# NUC400_v1 register map
File version: 1.0
NUC400_v1 SVD file
Registers are 32-bit, read-write, reset 0x0 unless marked. A register's access mark holds for its fields unless they carry their own. Offsets are from the block's base; lines under a group give offsets from that group; [hi:lo] are bit positions; {n}, {i} and the like mark numbered series; 'fields as' and 'values as' point back to an identical list; <NAME> marks a mode.

## Memory map
0x40000000 SYS blocks up to offset 0x104 — SYS Register Map
0x40000200 CLK blocks up to offset 0x74 — CLK Register Map
0x40000300 NMI size 0x8 — NMI Register Map
0x40004000 GPIO blocks up to offset 0xA40 — GPIO Register Map
0x40008000 PDMA blocks up to offset 0x490 — PDMA Register Map
0x40009000 USBH blocks up to offset 0x208 — USBH Register Map
0x4000B000 EMAC blocks up to offset 0x130 — EMAC Register Map
0x4000C000 FMC blocks up to offset 0xC8 — FMC Register Map
0x4000D000 SDH blocks up to offset 0x840 — SDH Register Map
0x40010000 EBI size 0x24 — EBI Register Map
0x40019000 USBD blocks up to offset 0x708 — USBD Register Map
0x40030000 CAP blocks up to offset 0x8C — CAP Register Map
0x40031000 CRC size 0x10 — CRC Register Map
0x40040000 WDT size 0x8 — WDT Register Map
0x40040100 WWDT size 0x10 — WWDT Register Map
0x40041000 RTC blocks up to offset 0x148 — RTC Register Map
0x40043000 ADC blocks up to offset 0x64 — ADC Register Map
0x40044000 EADC blocks up to offset 0x164 — EADC Register Map
0x40045000 ACMP size 0x14 — ACMP Register Map
0x40046000 OPA size 0x8 — OPS Register Map
0x40048000 I2S size 0x18 — I2S Register Map
0x4004D000 OTG size 0x14 — OTG Register Map
0x40050000 TIMER01 blocks up to offset 0x3C — TIMER Register Map
0x40051000 TIMER23 blocks up to offset 0x3C — TIMER Register Map
0x40058000 PWM0 blocks up to offset 0xF8 — PWM Register Map
0x40059000 PWM1 blocks up to offset 0xF8 — PWM Register Map
0x4005C000 EPWM0 size 0x48 — EPWM Register Map
0x4005D000 EPWM1 size 0x48 — EPWM Register Map
0x40060000 SPI0 blocks up to offset 0x34 — SPI Register Map
0x40061000 SPI1 blocks up to offset 0x34 — SPI Register Map
0x40062000 SPI2 blocks up to offset 0x34 — SPI Register Map
0x40063000 SPI3 blocks up to offset 0x34 — SPI Register Map
0x40070000 UART0 size 0x48 — UART Register Map
0x40071000 UART1 size 0x48 — UART Register Map
0x40072000 UART2 size 0x48 — UART Register Map
0x40073000 UART3 size 0x48 — UART Register Map
0x40074000 UART4 size 0x48 — UART Register Map
0x40075000 UART5 size 0x48 — UART Register Map
0x40080000 I2C0 blocks up to offset 0x44 — I2C Register Map
0x40081000 I2C1 blocks up to offset 0x44 — I2C Register Map
0x40082000 I2C2 blocks up to offset 0x44 — I2C Register Map
0x40083000 I2C3 blocks up to offset 0x44 — I2C Register Map
0x40084000 I2C4 blocks up to offset 0x44 — I2C Register Map
0x40090000 SC0 size 0x40 — SC Register Map
0x40091000 SC1 size 0x40 — SC Register Map
0x40092000 SC2 size 0x40 — SC Register Map
0x40093000 SC3 size 0x40 — SC Register Map
0x40094000 SC4 size 0x40 — SC Register Map
0x40095000 SC5 size 0x40 — SC Register Map
0x400A0000 CAN0 blocks up to offset 0x170 — CAN Register Map
0x400A1000 CAN1 blocks up to offset 0x170 — CAN Register Map
0x400B0000 QEI0 blocks up to offset 0x30 — QEI Register Map
0x400B1000 QEI1 blocks up to offset 0x30 — QEI Register Map
0x400B4000 ECAP0 size 0x20 — ECAP Register Map
0x400B5000 ECAP1 size 0x20 — ECAP Register Map
0x400E0000 PS2 size 0x20 — PS2 Register Map
0x50080000 CRYP blocks up to offset 0x358 — CRYPTO Register Map
0xE000E000 SCS blocks up to offset 0xD24 — SCS Register Map
0xE000E100 NVIC blocks up to offset 0xE04 — NVIC Register Map

## NVIC — NVIC Register Map
Base 0xE000E100
{0x0+4i} NVIC_ISER{i} (i=0..4) — IRQ0 ~ IRQ159 Set-enable Control Register
  [31:0] SETENA — Interrupt Set Enable Bit. The NVIC_ISER0-NVIC_ISER3 registers enable interrupts, and show which interrupts are enabled. Write:
    0=No effect. Interrupt Disabled; 1=Interrupt Enabled
{0x80+4i} NVIC_ICER{i} (i=0..4) — IRQ0 ~ IRQ159 Clear-enable Control Register
  [31:0] CLRENA — Interrupt Clear Enable Control. The NVIC_ICER0-NVIC_ICER3 registers disable interrupts, and show which interrupts are enabled. Write:
    0=No effect. Interrupt Disabled; 1=Interrupt Disabled. Interrupt Enabled
{0x100+4i} NVIC_ISPR{i} (i=0..4) — IRQ0 ~ IRQ159 Set-pending Control Register
  [31:0] SETPEND — Interrupt Set-Pending. The NVIC_ISPR0-NVIC_ISPR3 registers force interrupts into the pending state, and show which interrupts are pending. Write:
    0=No effect. Interrupt is not pending; 1=Changes interrupt state to pending. Interrupt is pending
{0x180+4i} NVIC_ICPR{i} (i=0..4) — IRQ0 ~ IRQ159 Clear-pending Control Register
  [31:0] CLRPEND — Interrupt Clear-Pending. The NVIC_ICPR0-NCVIC_ICPR3 registers remove the pending state from interrupts, and show which interrupts are pending. Write:
    0=No effect. Interrupt is not pending; 1=Removes pending state an interrupt. Interrupt is pending
{0x200+4i} NVIC_IABR{i} (i=0..4) — IRQ0 ~ IRQ159 Active Bit Register
  [31:0] ACTIVE — Interrupt Active Flags. The NVIC_IABR0-NVIC_IABR3 registers indicate which interrupts are active.
    0=interrupt not active; 1=interrupt active
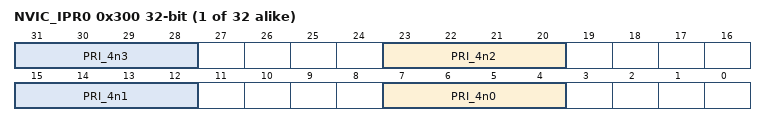
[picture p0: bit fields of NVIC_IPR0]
{0x300+4i} NVIC_IPR{i} (i=0..31) — IRQ0 ~ IRQ159 Interrupt Priority Control Register
  [8n+7:8n+4] PRI_4n{n} (n=0..3) — Priority Of IRQ_4n+{n} "0" denotes the highest priority and "15" denotes the lowest priority
0xE00 NVIC_STIR — Software Trigger Interrupt Registers
  [8:0] INTID — Interrupt ID. Write to the STIR To Generate An Interrupt from Software. When the USERSETMPEND bit in the SCR is set to 1, unprivileged software can access the STIR. Interrupt ID of the interrupt to trigger, in the range 0-63. For example, a value of 0x03 specifies interrupt IRQ3.
